VERSION ""

NS_ :

BS_:

BU_: DCU
VAL_TABLE_ TestMethod 10 "Two Pulse" 5 "Short Circuit" 0 "Not Selected" ;
VAL_TABLE_ DirCmd 1 "CCW" 0 "CW" ;
VAL_TABLE_ ClearFlt 3 "Clear Faults" 2 "TakeNoAction" 1 "TakeNoAction" 0 "TakeNoAction" ;
VAL_TABLE_ InverterEnable 3 "Turn ON" 2 "Not Valid" 1 "Not Valid" 0 "Turn OFF" ;
VAL_TABLE_ Motor_SM 32768 "Fault" 16384 "Stop to Fault" 1024 "Resolver Calibration" 512 "Stop to Idle" 256 "Stop" 128 "Any Stop" 64 "Run" 32 "Start Run" 16 "Clear" 8 "Offset_Calibration" 4 "Idle Start" 2 "Idle" 0 "Init" ;
VAL_TABLE_ FltStates 240 "Stopped by fault" 4 "Fault Critical" 2 "Fault" 1 "Warning" 0 "No Faults" ;
VAL_TABLE_ MotorCommand 3 "Not Valid" 2 "Motor Stop" 1 "Motor Start" 0 "Not Valid" ;
VAL_TABLE_ CntrlMode 3 "Not Valid" 2 "Torque Mode" 1 "Speed Mode" 0 "Not Selected" ;
VAL_TABLE_ OperationMode 3 "MotorControl" 2 "ActiveDischarge" 1 "Calibration" 0 "Not Selected" ;
VAL_TABLE_ Precharge 1 "Charged" 0 "Discharged" ;
VAL_TABLE_ Ready 1 "Ready" 0 "Not Ready" ;
VAL_TABLE_ Initialization 1 "Initialized" 0 "Not Initialized" ;
VAL_TABLE_ Inverter_SM 32768 "Fault" 16384 "Stop_To_Fault" 128 "ActiveDischarge" 64 "Calibration" 32 "Stop_To_Idle" 16 "Run_Torque_Control" 8 "Run_Speed_Control" 4 "Start" 2 "Idle" 1 "Precharge" 0 "Initialization" ;

BO_ 3221225472 VECTOR__INDEPENDENT_SIG_MSG: 0 Vector__XXX
 SG_ IgbtTestSideSelector : 0|1@1+ (1,0) [0|1] "" Vector__XXX

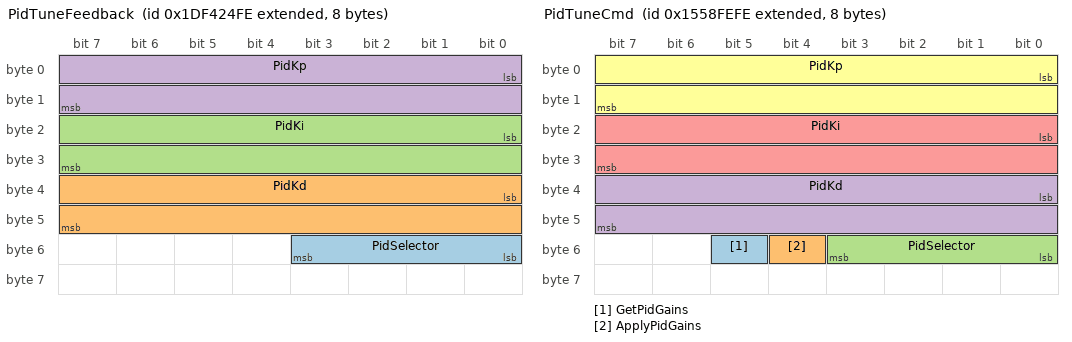
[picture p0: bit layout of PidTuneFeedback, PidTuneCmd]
BO_ 2650023166 PidTuneFeedback: 8 Vector__XXX
 SG_ PidSelector : 48|4@1+ (1,0) [0|15] "" Vector__XXX
 SG_ PidKd : 32|16@1+ (1,0) [0|65535] "" Vector__XXX
 SG_ PidKi : 16|16@1+ (1,0) [0|65535] "" Vector__XXX
 SG_ PidKp : 0|16@1+ (1,0) [0|65535] "" Vector__XXX

BO_ 2505637630 PidTuneCmd: 8 Vector__XXX
 SG_ GetPidGains : 53|1@1+ (1,0) [0|1] "" Vector__XXX
 SG_ ApplyPidGains : 52|1@1+ (1,0) [0|1] "" Vector__XXX
 SG_ PidSelector : 48|4@1+ (1,0) [0|15] "" Vector__XXX
 SG_ PidKd : 32|16@1+ (1,0) [0|65535] "" Vector__XXX
 SG_ PidKi : 16|16@1+ (1,0) [0|65535] "" Vector__XXX
 SG_ PidKp : 0|16@1+ (1,0) [0|65535] "" Vector__XXX

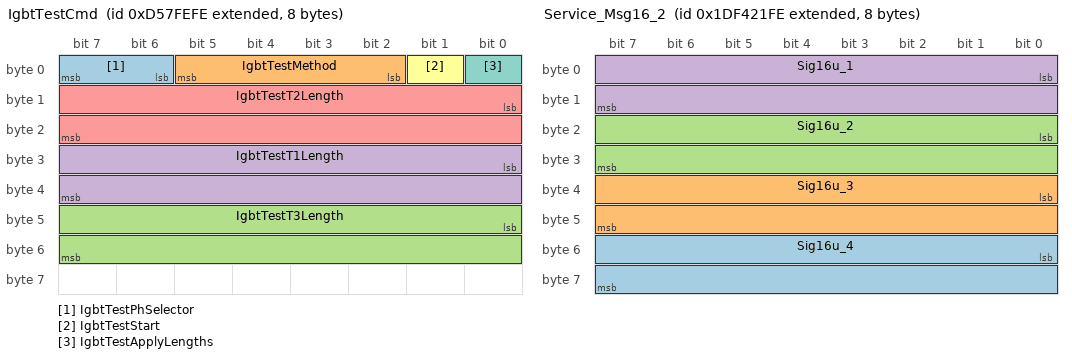
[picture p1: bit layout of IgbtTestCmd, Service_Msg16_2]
BO_ 2371354366 IgbtTestCmd: 8 Vector__XXX
 SG_ IgbtTestPhSelector : 6|2@1+ (1,0) [0|3] "" Vector__XXX
 SG_ IgbtTestMethod : 2|4@1+ (1,0) [0|15] "" Vector__XXX
 SG_ IgbtTestT3Length : 40|16@1+ (1,0) [0|65535] "" Vector__XXX
 SG_ IgbtTestT1Length : 24|16@1+ (1,0) [0|65535] "" Vector__XXX
 SG_ IgbtTestT2Length : 8|16@1+ (1,0) [0|65535] "" Vector__XXX
 SG_ IgbtTestStart : 1|1@1+ (1,0) [0|1] "" Vector__XXX
 SG_ IgbtTestApplyLengths : 0|1@1+ (1,0) [0|1] "" Vector__XXX

BO_ 2650022910 Service_Msg32_2: 8 Vector__XXX
 SG_ Sig32u_2 : 32|32@1+ (1,0) [0|4294967295] "" Vector__XXX
 SG_ Sig32u_1 : 0|32@1+ (1,0) [0|4294967295] "" Vector__XXX

BO_ 2650022654 Service_Msg32_1: 8 Vector__XXX
 SG_ Sig32_2 : 32|32@1+ (1,0) [0|4294967295] "" Vector__XXX
 SG_ Sig32_1 : 0|32@1+ (1,0) [0|4294967295] "" Vector__XXX

BO_ 2650022398 Service_Msg16_2: 8 Vector__XXX
 SG_ Sig16u_4 : 48|16@1+ (1,0) [0|65535] "" Vector__XXX
 SG_ Sig16u_3 : 32|16@1+ (1,0) [0|65535] "" Vector__XXX
 SG_ Sig16u_2 : 16|16@1+ (1,0) [0|65535] "" Vector__XXX
 SG_ Sig16u_1 : 0|16@1+ (1,0) [0|65535] "" Vector__XXX

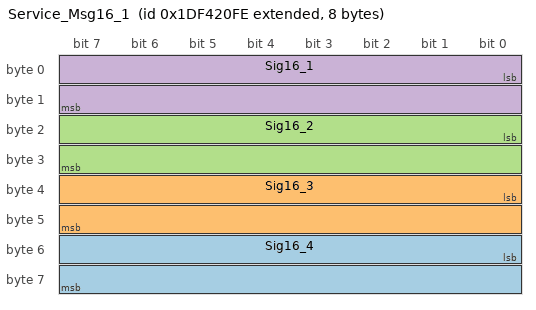
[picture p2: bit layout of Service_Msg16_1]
BO_ 2650022142 Service_Msg16_1: 8 Vector__XXX
 SG_ Sig16_4 : 48|16@1+ (1,-32768) [-32768|32767] "" Vector__XXX
 SG_ Sig16_3 : 32|16@1+ (1,-32768) [-32768|32767] "" Vector__XXX
 SG_ Sig16_2 : 16|16@1+ (1,-32768) [-32768|32767] "" Vector__XXX
 SG_ Sig16_1 : 0|16@1+ (1,-32768) [-32768|32767] "" Vector__XXX

CM_ BO_ 3221225472 "This is a message for not used signals, created by Vector CANdb++ DBC OLE DB Provider.";
CM_ SG_ 3221225472 IgbtTestSideSelector "Switch selection signal which will be permanently open during the short circuit test";
CM_ SG_ 2650023166 PidSelector "Tunable PID selector";
CM_ SG_ 2650023166 PidKd "PID differential gain value";
CM_ SG_ 2650023166 PidKi "PID integral gain value";
CM_ SG_ 2650023166 PidKp "PID proportional gain value";
CM_ SG_ 2505637630 GetPidGains "Get PID gains for selected PID to show in PidTuneFeedback message";
CM_ SG_ 2505637630 ApplyPidGains "Apply PID gains for selected PID";
CM_ SG_ 2505637630 PidSelector "Tunable PID selector";
CM_ SG_ 2505637630 PidKd "PID differential gain value";
CM_ SG_ 2505637630 PidKi "PID integral gain value";
CM_ SG_ 2505637630 PidKp "PID proportional gain value";
CM_ BO_ 2371354366 "Command message for two pulse test";
CM_ SG_ 2371354366 IgbtTestPhSelector "Phase selector signal";
CM_ SG_ 2371354366 IgbtTestMethod "IGBT Test Method 0x0 - Not Selected; 0x5 - Short Circuit; 0xA - Two Pulse";
CM_ SG_ 2371354366 IgbtTestT3Length "The length of the second pulse in two pulse test";
CM_ SG_ 2371354366 IgbtTestT1Length "The length of the first pulse in two pulse test";
CM_ SG_ 2371354366 IgbtTestT2Length "The length of thegap between first and second pulses in two pulses test";
CM_ SG_ 2371354366 IgbtTestStart "Test start command";
CM_ SG_ 2371354366 IgbtTestApplyLengths "Apply configuration command";
CM_ SG_ 2650022910 Sig32u_2 "Debug uint32_t value";
CM_ SG_ 2650022910 Sig32u_1 "Debug uint32_t value";
CM_ SG_ 2650022654 Sig32_2 "Debug int32_t value";
CM_ SG_ 2650022654 Sig32_1 "Debug int32_t value";
CM_ SG_ 2650022398 Sig16u_4 "Debug uint16_t value";
CM_ SG_ 2650022398 Sig16u_3 "Debug uint16_t value";
CM_ SG_ 2650022398 Sig16u_2 "Debug uint16_t value";
CM_ SG_ 2650022398 Sig16u_1 "Debug uint16_t value";
CM_ SG_ 2650022142 Sig16_4 "Debug int16_t value";
CM_ SG_ 2650022142 Sig16_3 "Debug int16_t value";
CM_ SG_ 2650022142 Sig16_2 "Debug int16_t value";
CM_ SG_ 2650022142 Sig16_1 "Debug int16_t value";
BA_DEF_ BO_  "PpCcGenMsgType" STRING ;
BA_DEF_ SG_  "SigType" ENUM  "Default","Range","RangeSigned","ASCII","Discrete","Control","ReferencePGN","DTC","StringDelimiter","StringLength","StringLengthControl","MessageCounter","MessageChecksum";
BA_DEF_ SG_  "GenSigEVName" STRING ;
BA_DEF_ SG_  "GenSigILSupport" ENUM  "No","Yes";
BA_DEF_ SG_  "GenSigSendType" ENUM  "Cyclic","OnWrite","OnWriteWithRepetition","OnChange","OnChangeWithRepetition","IfActive","IfActiveWithRepetition","NoSigSendType";
BA_DEF_ SG_  "GenSigStartValue" INT 0 2147483647;
BA_DEF_ BO_  "GenMsgILSupport" ENUM  "No","Yes";
BA_DEF_ BU_  "NmStationAddress" INT 0 255;
BA_DEF_ BO_  "GenMsgSendType" ENUM  "cyclic","NotUsed","IfActive","NotUsed","NotUsed","NotUsed","NotUsed","NotUsed","noMsgSendType";
BA_DEF_ BO_  "GenMsgRequestable" INT 0 1;
BA_DEF_ BO_  "GenMsgCycleTime" INT 0 3600000;
BA_DEF_  "DBName" STRING ;
BA_DEF_  "BusType" STRING ;
BA_DEF_  "ProtocolType" STRING ;
BA_DEF_ BO_  "VFrameFormat" ENUM  "StandardCAN","ExtendedCAN","reserved","J1939PG";
BA_DEF_DEF_  "PpCcGenMsgType" "PpCcUndefined";
BA_DEF_DEF_  "SigType" "Default";
BA_DEF_DEF_  "GenSigEVName" "Env@Nodename_@Signame";
BA_DEF_DEF_  "GenSigILSupport" "Yes";
BA_DEF_DEF_  "GenSigSendType" "NoSigSendType";
BA_DEF_DEF_  "GenSigStartValue" 0;
BA_DEF_DEF_  "GenMsgILSupport" "Yes";
BA_DEF_DEF_  "NmStationAddress" 254;
BA_DEF_DEF_  "GenMsgSendType" "noMsgSendType";
BA_DEF_DEF_  "GenMsgRequestable" 1;
BA_DEF_DEF_  "GenMsgCycleTime" 0;
BA_DEF_DEF_  "DBName" "";
BA_DEF_DEF_  "BusType" "CAN";
BA_DEF_DEF_  "ProtocolType" "J1939";
BA_DEF_DEF_  "VFrameFormat" "J1939PG";
BA_ "DBName" "Traction_Inverter";
BA_ "NmStationAddress" BU_ DCU 100;
BA_ "GenMsgCycleTime" BO_ 2650023166 10;
BA_ "PpCcGenMsgType" BO_ 2650023166 "PpCcOutput";
BA_ "PpCcGenMsgType" BO_ 2505637630 "PpCcInput";
BA_ "PpCcGenMsgType" BO_ 2371354366 "PpCcUnused";
BA_ "GenMsgCycleTime" BO_ 2650022910 10;
BA_ "PpCcGenMsgType" BO_ 2650022910 "PpCcOutput";
BA_ "GenMsgCycleTime" BO_ 2650022654 10;
BA_ "PpCcGenMsgType" BO_ 2650022654 "PpCcOutput";
BA_ "GenMsgCycleTime" BO_ 2650022398 10;
BA_ "PpCcGenMsgType" BO_ 2650022398 "PpCcOutput";
BA_ "GenMsgCycleTime" BO_ 2650022142 10;
BA_ "PpCcGenMsgType" BO_ 2650022142 "PpCcOutput";
BA_ "GenSigStartValue" SG_ 2650022142 Sig16_4 32768;
BA_ "GenSigStartValue" SG_ 2650022142 Sig16_3 32768;
BA_ "GenSigStartValue" SG_ 2650022142 Sig16_2 32768;
BA_ "GenSigStartValue" SG_ 2650022142 Sig16_1 32768;
VAL_ 3221225472 IgbtTestSideSelector 1 "High" 0 "Low" ;
VAL_ 2650023166 PidSelector 5 "SpeedLim" 4 "FW" 3 "Speed" 2 "i_d" 1 "i_q" 0 "Not selected" ;
VAL_ 2505637630 PidSelector 5 "SpeedLim" 4 "FW" 3 "Speed" 2 "i_d" 1 "i_q" 0 "Not selected" ;
VAL_ 2371354366 IgbtTestPhSelector 1 "Phase V" 2 "Phase W" 0 "Phase U" ;
VAL_ 2371354366 IgbtTestMethod 11 "P2P Short Circuit Low" 10 "P2P Short Circuit High" 9 "Short Circuit High" 1 "Double Pulse" 5 "Short Circuit Low" 0 "Not Selected" ;
